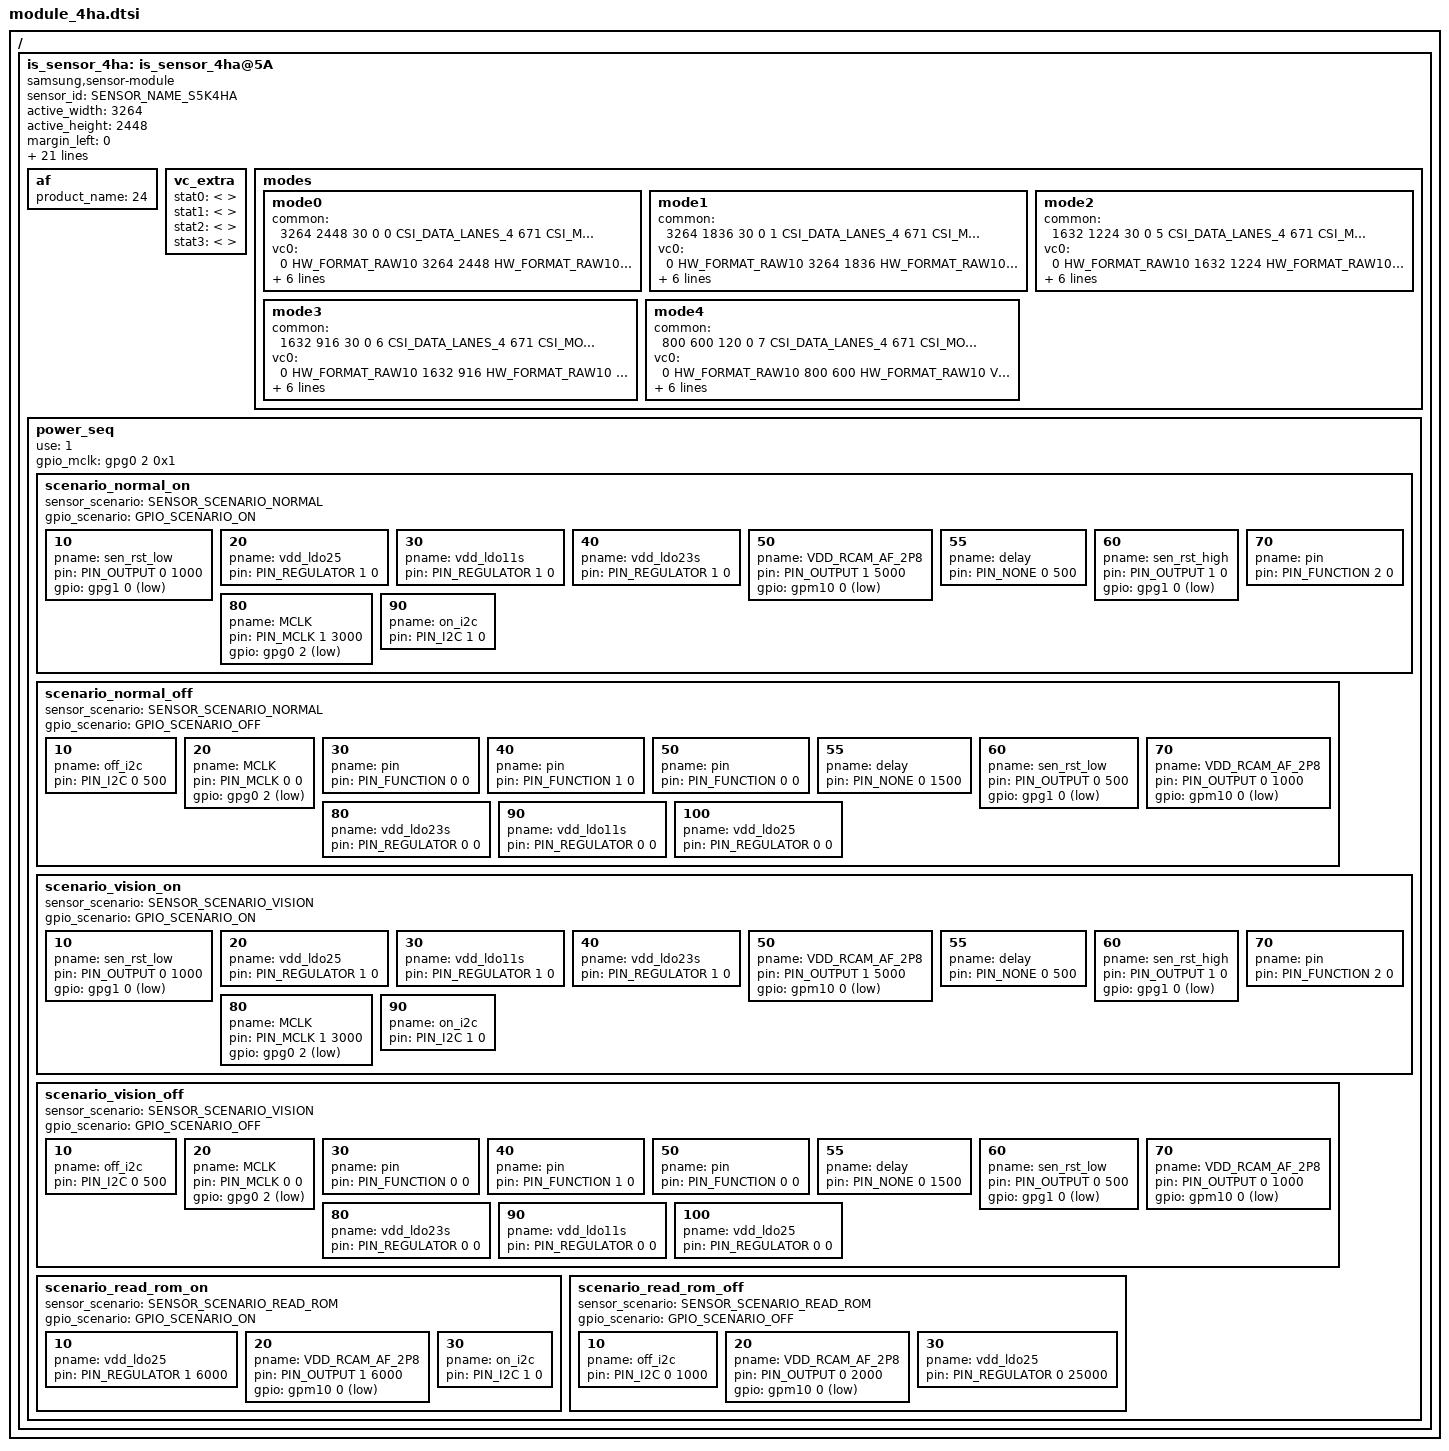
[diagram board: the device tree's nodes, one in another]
/*
 * SAMSUNG EXYNOSxxxx board camera device tree source
 *
 * Copyright (c) 2023 Samsung Electronics Co., Ltd.
 *		http://www.samsung.com
 *
 * This program is free software; you can redistribute it and/or modify
 * it under the terms of the GNU General Public License version 2 as
 * published by the Free Software Foundation.
 */

#include <dt-bindings/camera/exynos_is_dt.h>

/ {
	fragment@camera {
		target-path = "/";
		__overlay__ {
			is_sensor_4ha: is_sensor_4ha@5A {
				compatible = "samsung,sensor-module";

				/* common */
				sensor_id = <SENSOR_NAME_S5K4HA>;
				active_width = <3264>;
				active_height = <2448>;
				margin_left = <0>;
				margin_right = <0>;
				margin_top = <0>;
				margin_bottom = <0>;
				max_framerate = <120>;
				bitwidth = <10>;
				use_retention_mode = <SENSOR_RETENTION_UNSUPPORTED>;
				sensor_maker = "SLSI";
				sensor_name = "4HA";
				setfile_name = "setfile_4ha.bin";

				status = "okay";

				/* board */
				pinctrl-names = "pin0", "pin1", "pin2", "release";
				pinctrl-0 = <>;
				pinctrl-1 = <&sensor_mclk0_out>;
				pinctrl-2 = <&sensor_mclk0_fn>;
				pinctrl-3 = <>;

				position = <0>;	/* Rear:0. Front:1. Rear_sub:2. Secure:3. */
				id = <0>; /* is_sensor id */
				mclk_ch = <0>;
				sensor_i2c_ch = <1>; /* SENSOR_CONTROL_I2C1 */

				/* vendor */
				rom_type = <2>; /* ROM_TYPE_EEPROM */
				rom_id = <0>;
				rom_cal_index = <0>;

				af {
					product_name = <24>; /* ACTUATOR_NAME_DW9808 */
					//i2c_ch = <6>; /* SENSOR_CONTROL_I2C6 */
				};

				vc_extra {
					/* ex) statX = <stat_type, sensor_mode, max_width, max_height, max_element> */
					stat0 = </* not available */>;	/* VC_BUF_DATA_TYPE_SENSOR_STAT1 */
					stat1 = </* not available */>;	/* VC_BUF_DATA_TYPE_GENERAL_STAT1 */
					stat2 = </* not available */>;	/* VC_BUF_DATA_TYPE_SENSOR_STAT2 */
					stat3 = </* not available */>;	/* VC_BUF_DATA_TYPE_GENERAL_STAT2 */
				};

				/* sensor modes */
				modes {
					/* common = <width, height, fps, settle, mode, lane, speed, interleave, lrte, pd_mode> */
					/* vcX = <map, hwformat, width, height, hwformat, type, width, height> */
					mode0 {/* A-1 */
						common = <3264 2448 30 0 0 CSI_DATA_LANES_4 671 CSI_MODE_DT_ONLY LRTE_DISABLE PD_NONE EX_NONE>;
						vc0 = </* in */ 0 HW_FORMAT_RAW10 3264 2448    /* out */ HW_FORMAT_RAW10 VC_NOTHING 0 0>;
						vc1 = </* in */ 1 HW_FORMAT_UNKNOWN 0 0        /* out */ HW_FORMAT_UNKNOWN VC_NOTHING 0 0>;
						vc2 = </* in */ 2 HW_FORMAT_EMBEDDED_8BIT 0 0        /* out */ HW_FORMAT_UNKNOWN VC_NOTHING 0 0>; 
						vc3 = </* in */ 3 HW_FORMAT_UNKNOWN 0 0        /* out */ HW_FORMAT_UNKNOWN VC_NOTHING 0 0>;
					};
					mode1 {/* K-1 */
						common = <3264 1836 30 0 1 CSI_DATA_LANES_4 671 CSI_MODE_VC_ONLY LRTE_DISABLE PD_NONE>;
						vc0 = </* in */ 0 HW_FORMAT_RAW10 3264 1836    /* out */ HW_FORMAT_RAW10 VC_NOTHING 0 0>;
						vc1 = </* in */ 1 HW_FORMAT_UNKNOWN 0 0        /* out */ HW_FORMAT_UNKNOWN VC_NOTHING 0 0>;
						vc2 = </* in */ 2 HW_FORMAT_EMBEDDED_8BIT 0 0        /* out */ HW_FORMAT_UNKNOWN VC_NOTHING 0 0>;
						vc3 = </* in */ 3 HW_FORMAT_UNKNOWN 0 0        /* out */ HW_FORMAT_UNKNOWN VC_NOTHING 0 0>;
					};
					mode2 {/* M-1 */
						common = <1632 1224 30 0 5 CSI_DATA_LANES_4 671 CSI_MODE_VC_ONLY LRTE_DISABLE PD_NONE>;
						vc0 = </* in */ 0 HW_FORMAT_RAW10 1632 1224    /* out */ HW_FORMAT_RAW10 VC_NOTHING 0 0>;
						vc1 = </* in */ 1 HW_FORMAT_UNKNOWN 0 0        /* out */ HW_FORMAT_UNKNOWN VC_NOTHING 0 0>;
						vc2 = </* in */ 2 HW_FORMAT_EMBEDDED_8BIT 0 0        /* out */ HW_FORMAT_UNKNOWN VC_NOTHING 0 0>;
						vc3 = </* in */ 3 HW_FORMAT_UNKNOWN 0 0        /* out */ HW_FORMAT_UNKNOWN VC_NOTHING 0 0>;
					};
					mode3 {/* M-1 */
						common = <1632 916 30 0 6 CSI_DATA_LANES_4 671 CSI_MODE_VC_ONLY LRTE_DISABLE PD_NONE>;
						vc0 = </* in */ 0 HW_FORMAT_RAW10 1632 916    /* out */ HW_FORMAT_RAW10 VC_NOTHING 0 0>;
						vc1 = </* in */ 1 HW_FORMAT_UNKNOWN 0 0        /* out */ HW_FORMAT_UNKNOWN VC_NOTHING 0 0>;
						vc2 = </* in */ 2 HW_FORMAT_EMBEDDED_8BIT 0 0        /* out */ HW_FORMAT_UNKNOWN VC_NOTHING 0 0>;
						vc3 = </* in */ 3 HW_FORMAT_UNKNOWN 0 0        /* out */ HW_FORMAT_UNKNOWN VC_NOTHING 0 0>;
					};
					mode4 {/* M-1 */
						common = <800 600 120 0 7 CSI_DATA_LANES_4 671 CSI_MODE_VC_ONLY LRTE_DISABLE PD_NONE>;
						vc0 = </* in */ 0 HW_FORMAT_RAW10 800 600    /* out */ HW_FORMAT_RAW10 VC_NOTHING 0 0>;
						vc1 = </* in */ 1 HW_FORMAT_UNKNOWN 0 0        /* out */ HW_FORMAT_UNKNOWN VC_NOTHING 0 0>;
						vc2 = </* in */ 2 HW_FORMAT_EMBEDDED_8BIT 0 0       /* out */ HW_FORMAT_UNKNOWN VC_NOTHING 0 0>;
						vc3 = </* in */ 3 HW_FORMAT_UNKNOWN 0 0        /* out */ HW_FORMAT_UNKNOWN VC_NOTHING 0 0>;
					};
				};

				power_seq {
					use = <1>;
					gpio_mclk = <&gpg0 2 0x1>;
					scenario_normal_on {
						sensor_scenario = <SENSOR_SCENARIO_NORMAL>;
						gpio_scenario = <GPIO_SCENARIO_ON>;
						/* A start node number should be over the 10 for reserved number 0~9. */
						/* pname = "name"; pin = <act value delay voltage>; gpio = <gpx# # 0x1>; */
						10 { pname = "sen_rst_low"; pin = <PIN_OUTPUT 0 1000>; gpio = <&gpg1 0 0x1>; };
						20 { pname = "vdd_ldo25"; pin = <PIN_REGULATOR 1 0>; };
						30 { pname = "vdd_ldo11s"; pin = <PIN_REGULATOR 1 0>; };
						40 { pname = "vdd_ldo23s"; pin = <PIN_REGULATOR 1 0>; };
						50 { pname = "VDD_RCAM_AF_2P8"; pin = <PIN_OUTPUT 1 5000>; gpio = <&gpm10 0 0x1>; };
						55 { pname = "delay"; pin = <PIN_NONE 0 500>; };
						60 { pname = "sen_rst_high"; pin = <PIN_OUTPUT 1 0>; gpio = <&gpg1 0 0x1>; };
						70 { pname = "pin"; pin = <PIN_FUNCTION 2 0>; };
						80 { pname = "MCLK"; pin = <PIN_MCLK 1 3000>; gpio = <&gpg0 2 0x1>; };
						90 { pname = "on_i2c"; pin = <PIN_I2C 1 0>; };
					};

					scenario_normal_off {
						sensor_scenario = <SENSOR_SCENARIO_NORMAL>;
						gpio_scenario = <GPIO_SCENARIO_OFF>;
						/* A start node number should be over the 10 for reserved number 0~9. */
						/* pname = "name"; pin = <act value delay voltage>; gpio = <gpx# # 0x1>; */
						10 { pname = "off_i2c"; pin = <PIN_I2C 0 500>; };
						20 { pname = "MCLK"; pin = <PIN_MCLK 0 0>; gpio = <&gpg0 2 0x1>; };
						30 { pname = "pin"; pin = <PIN_FUNCTION 0 0>; };
						40 { pname = "pin"; pin = <PIN_FUNCTION 1 0>; };
						50 { pname = "pin"; pin = <PIN_FUNCTION 0 0>; };
						55 { pname = "delay"; pin = <PIN_NONE 0 1500>; };
						60 { pname = "sen_rst_low"; pin = <PIN_OUTPUT 0 500>; gpio = <&gpg1 0 0x1>; };
						70 { pname = "VDD_RCAM_AF_2P8"; pin = <PIN_OUTPUT 0 1000>; gpio = <&gpm10 0 0x1>; };
						80 { pname = "vdd_ldo23s"; pin = <PIN_REGULATOR 0 0>; };
						90 { pname = "vdd_ldo11s"; pin = <PIN_REGULATOR 0 0>; };
						100 { pname = "vdd_ldo25"; pin = <PIN_REGULATOR 0 0>; };
					};

					scenario_vision_on {
						sensor_scenario = <SENSOR_SCENARIO_VISION>;
						gpio_scenario = <GPIO_SCENARIO_ON>;
						/* A start node number should be over the 10 for reserved number 0~9. */
						/* pname = "name"; pin = <act value delay voltage>; gpio = <gpx# # 0x1>; */
						10 { pname = "sen_rst_low"; pin = <PIN_OUTPUT 0 1000>; gpio = <&gpg1 0 0x1>; };
						20 { pname = "vdd_ldo25"; pin = <PIN_REGULATOR 1 0>; };
						30 { pname = "vdd_ldo11s"; pin = <PIN_REGULATOR 1 0>; };
						40 { pname = "vdd_ldo23s"; pin = <PIN_REGULATOR 1 0>; };
						50 { pname = "VDD_RCAM_AF_2P8"; pin = <PIN_OUTPUT 1 5000>; gpio = <&gpm10 0 0x1>; };
						55 { pname = "delay"; pin = <PIN_NONE 0 500>; };
						60 { pname = "sen_rst_high"; pin = <PIN_OUTPUT 1 0>; gpio = <&gpg1 0 0x1>; };
						70 { pname = "pin"; pin = <PIN_FUNCTION 2 0>; };
						80 { pname = "MCLK"; pin = <PIN_MCLK 1 3000>; gpio = <&gpg0 2 0x1>; };
						90 { pname = "on_i2c"; pin = <PIN_I2C 1 0>; };
					};

					scenario_vision_off {
						sensor_scenario = <SENSOR_SCENARIO_VISION>;
						gpio_scenario = <GPIO_SCENARIO_OFF>;
						/* A start node number should be over the 10 for reserved number 0~9. */
						/* pname = "name"; pin = <act value delay voltage>; gpio = <gpx# # 0x1>; */
						10 { pname = "off_i2c"; pin = <PIN_I2C 0 500>; };
						20 { pname = "MCLK"; pin = <PIN_MCLK 0 0>; gpio = <&gpg0 2 0x1>; };
						30 { pname = "pin"; pin = <PIN_FUNCTION 0 0>; };
						40 { pname = "pin"; pin = <PIN_FUNCTION 1 0>; };
						50 { pname = "pin"; pin = <PIN_FUNCTION 0 0>; };
						55 { pname = "delay"; pin = <PIN_NONE 0 1500>; };
						60 { pname = "sen_rst_low"; pin = <PIN_OUTPUT 0 500>; gpio = <&gpg1 0 0x1>; };
						70 { pname = "VDD_RCAM_AF_2P8"; pin = <PIN_OUTPUT 0 1000>; gpio = <&gpm10 0 0x1>; };
						80 { pname = "vdd_ldo23s"; pin = <PIN_REGULATOR 0 0>; };
						90 { pname = "vdd_ldo11s"; pin = <PIN_REGULATOR 0 0>; };
						100 { pname = "vdd_ldo25"; pin = <PIN_REGULATOR 0 0>; };
					};

					scenario_read_rom_on {
						sensor_scenario = <SENSOR_SCENARIO_READ_ROM>;
						gpio_scenario = <GPIO_SCENARIO_ON>;
						/* A start node number should be over the 10 for reserved number 0~9. */
						/* pname = "name"; pin = <act value dealy voltage>; gpio = <gpx# # 0x1>; */
						10 { pname = "vdd_ldo25"; pin = <PIN_REGULATOR 1 6000>; };
						20 { pname = "VDD_RCAM_AF_2P8"; pin = <PIN_OUTPUT 1 6000>; gpio = <&gpm10 0 0x1>; };
						30 { pname = "on_i2c"; pin = <PIN_I2C 1 0>; };
					};

					scenario_read_rom_off {
						sensor_scenario = <SENSOR_SCENARIO_READ_ROM>;
						gpio_scenario = <GPIO_SCENARIO_OFF>;
						/* A start node number should be over the 10 for reserved number 0~9. */
						/* pname = "name"; pin = <act value dealy voltage>; gpio = <gpx# # 0x1>; */
						10 { pname = "off_i2c"; pin = <PIN_I2C 0 1000>; };
						20 { pname = "VDD_RCAM_AF_2P8"; pin = <PIN_OUTPUT 0 2000>; gpio = <&gpm10 0 0x1>; };
						30 { pname = "vdd_ldo25"; pin = <PIN_REGULATOR 0 25000>; };
					};
				};
			};
		}; /* end of __overlay__ */
	}; /* end of fragment */
}; /* end of root */
